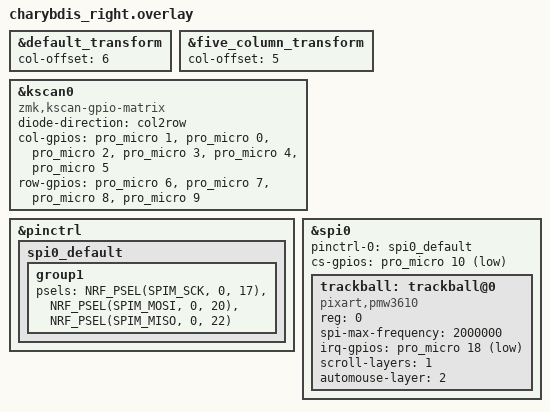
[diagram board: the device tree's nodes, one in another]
/*
 * Copyright (c) 2020 ZMK Contributors
 * SPDX-License-Identifier: MIT
 */

#include "charybdis.dtsi"
#include "pmw3610.dtsi"
#include <zephyr/dt-bindings/input/input-event-codes.h>
#include <dt-bindings/zmk/input_transform.h>

&default_transform {
    col-offset = <6>;
};

&five_column_transform {
    col-offset = <5>;
};

&kscan0 {
    compatible = "zmk,kscan-gpio-matrix";
    diode-direction = "col2row"; 

    col-gpios
        = <&pro_micro 1 GPIO_ACTIVE_HIGH>
        , <&pro_micro 0 GPIO_ACTIVE_HIGH>
        , <&pro_micro 2 GPIO_ACTIVE_HIGH>
        , <&pro_micro 3 GPIO_ACTIVE_HIGH>
        , <&pro_micro 4 GPIO_ACTIVE_HIGH>
        , <&pro_micro 5 GPIO_ACTIVE_HIGH>
        ;

    row-gpios
        = <&pro_micro 6 (GPIO_ACTIVE_HIGH | GPIO_PULL_DOWN)>
        , <&pro_micro 7 (GPIO_ACTIVE_HIGH | GPIO_PULL_DOWN)>
        , <&pro_micro 8 (GPIO_ACTIVE_HIGH | GPIO_PULL_DOWN)>
        , <&pro_micro 9 (GPIO_ACTIVE_HIGH | GPIO_PULL_DOWN)>
        ;
};

&pinctrl {
    spi0_default: spi0_default {
        group1 {
            psels = <NRF_PSEL(SPIM_SCK, 0, 17)>, 
                    <NRF_PSEL(SPIM_MOSI, 0, 20)>,
                    <NRF_PSEL(SPIM_MISO, 0, 22)>;
        };
    };
};

&spi0 {
    status = "okay";
    pinctrl-0 = <&spi0_default>;
    pinctrl-names = "default";
    cs-gpios = <&pro_micro 10 GPIO_ACTIVE_LOW>; 

    trackball: trackball@0 {
        status = "okay";
        compatible = "pixart,pmw3610"; /* Voltou ao normal sem o -alt */
        reg = <0>;
        spi-max-frequency = <2000000>;
        irq-gpios = <&pro_micro 18 (GPIO_ACTIVE_LOW | GPIO_PULL_UP)>; 
        
        /* O driver do Inorichi ainda aceita essas configurações antigas */
        scroll-layers = <1>; 
        automouse-layer = <2>; 
    };
};
